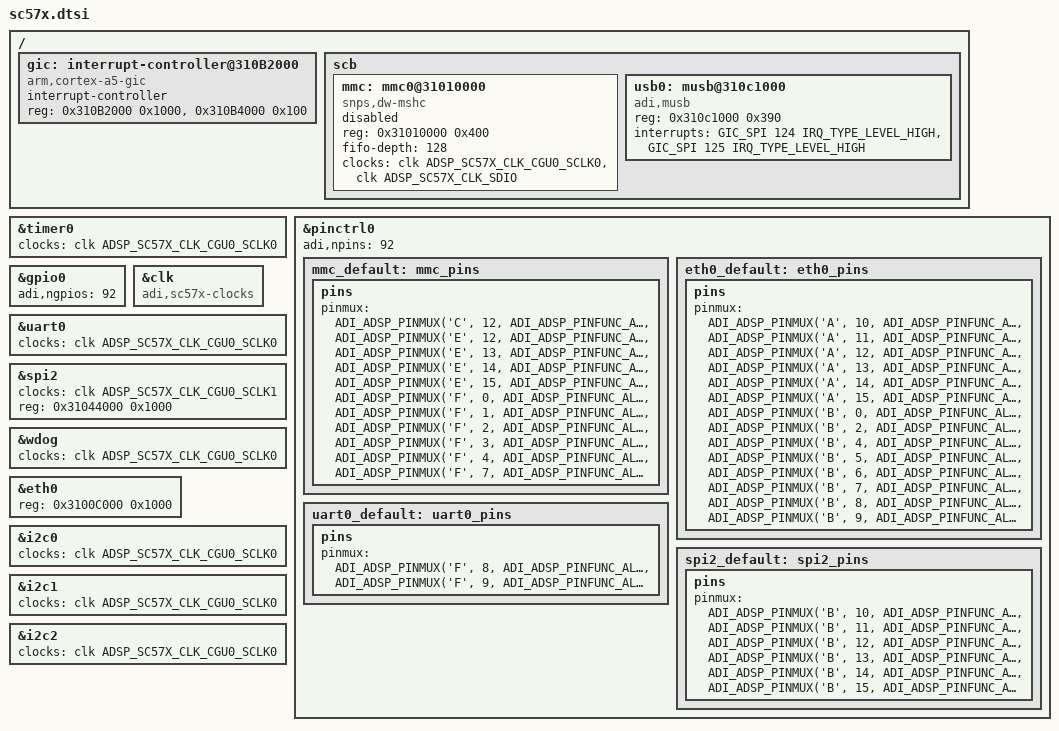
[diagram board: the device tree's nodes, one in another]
// SPDX-License-Identifier: GPL-2.0-or-later
/*
 * (C) Copyright 2024 - Analog Devices, Inc.
 */

/ {
	gic: interrupt-controller@310B2000 {
		compatible = "arm,cortex-a5-gic", "arm,cortex-a9-gic";
		#interrupt-cells = <3>;
		#address-cells = <0>;
		interrupt-controller;
		reg = <0x310B2000 0x1000>,
		      <0x310B4000 0x100>;
	};

	scb {
		mmc: mmc0@31010000 {
			compatible = "snps,dw-mshc";
			reg = <0x31010000 0x400>;
			fifo-depth = <128>;
			clock-names = "biu", "ciu";
			status = "disabled";
		};

		usb0: musb@310c1000 {
			compatible = "adi,musb";
			reg = <0x310c1000 0x390>;
			interrupts = <GIC_SPI 124 IRQ_TYPE_LEVEL_HIGH>,
						 <GIC_SPI 125 IRQ_TYPE_LEVEL_HIGH>;
			interrupt-names = "mc", "dma";
			status = "okay";
		};

	};
};

&timer0 {
	clocks = <&clk ADSP_SC57X_CLK_CGU0_SCLK0>;
};

&pinctrl0 {
	mmc_default: mmc_pins {
		pins {
			pinmux = <ADI_ADSP_PINMUX('C', 12, ADI_ADSP_PINFUNC_ALT1)>,
				 <ADI_ADSP_PINMUX('E', 12, ADI_ADSP_PINFUNC_ALT0)>,
				 <ADI_ADSP_PINMUX('E', 13, ADI_ADSP_PINFUNC_ALT0)>,
				 <ADI_ADSP_PINMUX('E', 14, ADI_ADSP_PINFUNC_ALT0)>,
				 <ADI_ADSP_PINMUX('E', 15, ADI_ADSP_PINFUNC_ALT0)>,
				 <ADI_ADSP_PINMUX('F', 0, ADI_ADSP_PINFUNC_ALT0)>,
				 <ADI_ADSP_PINMUX('F', 1, ADI_ADSP_PINFUNC_ALT0)>,
				 <ADI_ADSP_PINMUX('F', 2, ADI_ADSP_PINFUNC_ALT0)>,
				 <ADI_ADSP_PINMUX('F', 3, ADI_ADSP_PINFUNC_ALT0)>,
				 <ADI_ADSP_PINMUX('F', 4, ADI_ADSP_PINFUNC_ALT0)>,
				 <ADI_ADSP_PINMUX('F', 7, ADI_ADSP_PINFUNC_ALT2)>;
		};
	};

	eth0_default: eth0_pins {
		pins {
			pinmux = <ADI_ADSP_PINMUX('A', 10, ADI_ADSP_PINFUNC_ALT0)>,
				 <ADI_ADSP_PINMUX('A', 11, ADI_ADSP_PINFUNC_ALT0)>,
				 <ADI_ADSP_PINMUX('A', 12, ADI_ADSP_PINFUNC_ALT0)>,
				 <ADI_ADSP_PINMUX('A', 13, ADI_ADSP_PINFUNC_ALT0)>,
				 <ADI_ADSP_PINMUX('A', 14, ADI_ADSP_PINFUNC_ALT0)>,
				 <ADI_ADSP_PINMUX('A', 15, ADI_ADSP_PINFUNC_ALT0)>,
				 <ADI_ADSP_PINMUX('B', 0, ADI_ADSP_PINFUNC_ALT0)>,
				 <ADI_ADSP_PINMUX('B', 2, ADI_ADSP_PINFUNC_ALT0)>,
				 <ADI_ADSP_PINMUX('B', 4, ADI_ADSP_PINFUNC_ALT0)>,
				 <ADI_ADSP_PINMUX('B', 5, ADI_ADSP_PINFUNC_ALT0)>,
				 <ADI_ADSP_PINMUX('B', 6, ADI_ADSP_PINFUNC_ALT0)>,
				 <ADI_ADSP_PINMUX('B', 7, ADI_ADSP_PINFUNC_ALT0)>,
				 <ADI_ADSP_PINMUX('B', 8, ADI_ADSP_PINFUNC_ALT0)>,
				 <ADI_ADSP_PINMUX('B', 9, ADI_ADSP_PINFUNC_ALT0)>;
		};
	};

	uart0_default: uart0_pins {
		bootph-pre-ram;
		pins {
			bootph-pre-ram;
			pinmux = <ADI_ADSP_PINMUX('F', 8, ADI_ADSP_PINFUNC_ALT0)>,
				 <ADI_ADSP_PINMUX('F', 9, ADI_ADSP_PINFUNC_ALT0)>;
		};
	};

	spi2_default: spi2_pins {
		pins {
			pinmux = <ADI_ADSP_PINMUX('B', 10, ADI_ADSP_PINFUNC_ALT0)>,
				 <ADI_ADSP_PINMUX('B', 11, ADI_ADSP_PINFUNC_ALT0)>,
				 <ADI_ADSP_PINMUX('B', 12, ADI_ADSP_PINFUNC_ALT0)>,
				 <ADI_ADSP_PINMUX('B', 13, ADI_ADSP_PINFUNC_ALT0)>,
				 <ADI_ADSP_PINMUX('B', 14, ADI_ADSP_PINFUNC_ALT0)>,
				 <ADI_ADSP_PINMUX('B', 15, ADI_ADSP_PINFUNC_ALT0)>;
		};
	};
};

&pinctrl0 {
	adi,npins = <92>;
};

&gpio0 {
	adi,ngpios = <92>;
};

&clk {
	compatible = "adi,sc57x-clocks";
};

&uart0 {
	clocks = <&clk ADSP_SC57X_CLK_CGU0_SCLK0>;
};

&spi2 {
	clocks = <&clk ADSP_SC57X_CLK_CGU0_SCLK1>;
	reg = <0x31044000 0x1000>;
};

&wdog {
	clocks = <&clk ADSP_SC57X_CLK_CGU0_SCLK0>;
};

&eth0 {
	reg = <0x3100C000 0x1000>;
};

&mmc {
	clocks = <&clk ADSP_SC57X_CLK_CGU0_SCLK0>, <&clk ADSP_SC57X_CLK_SDIO>;
};

&i2c0 {
	clocks = <&clk ADSP_SC57X_CLK_CGU0_SCLK0>;
};

&i2c1 {
	clocks = <&clk ADSP_SC57X_CLK_CGU0_SCLK0>;
};

&i2c2 {
	clocks = <&clk ADSP_SC57X_CLK_CGU0_SCLK0>;
};
